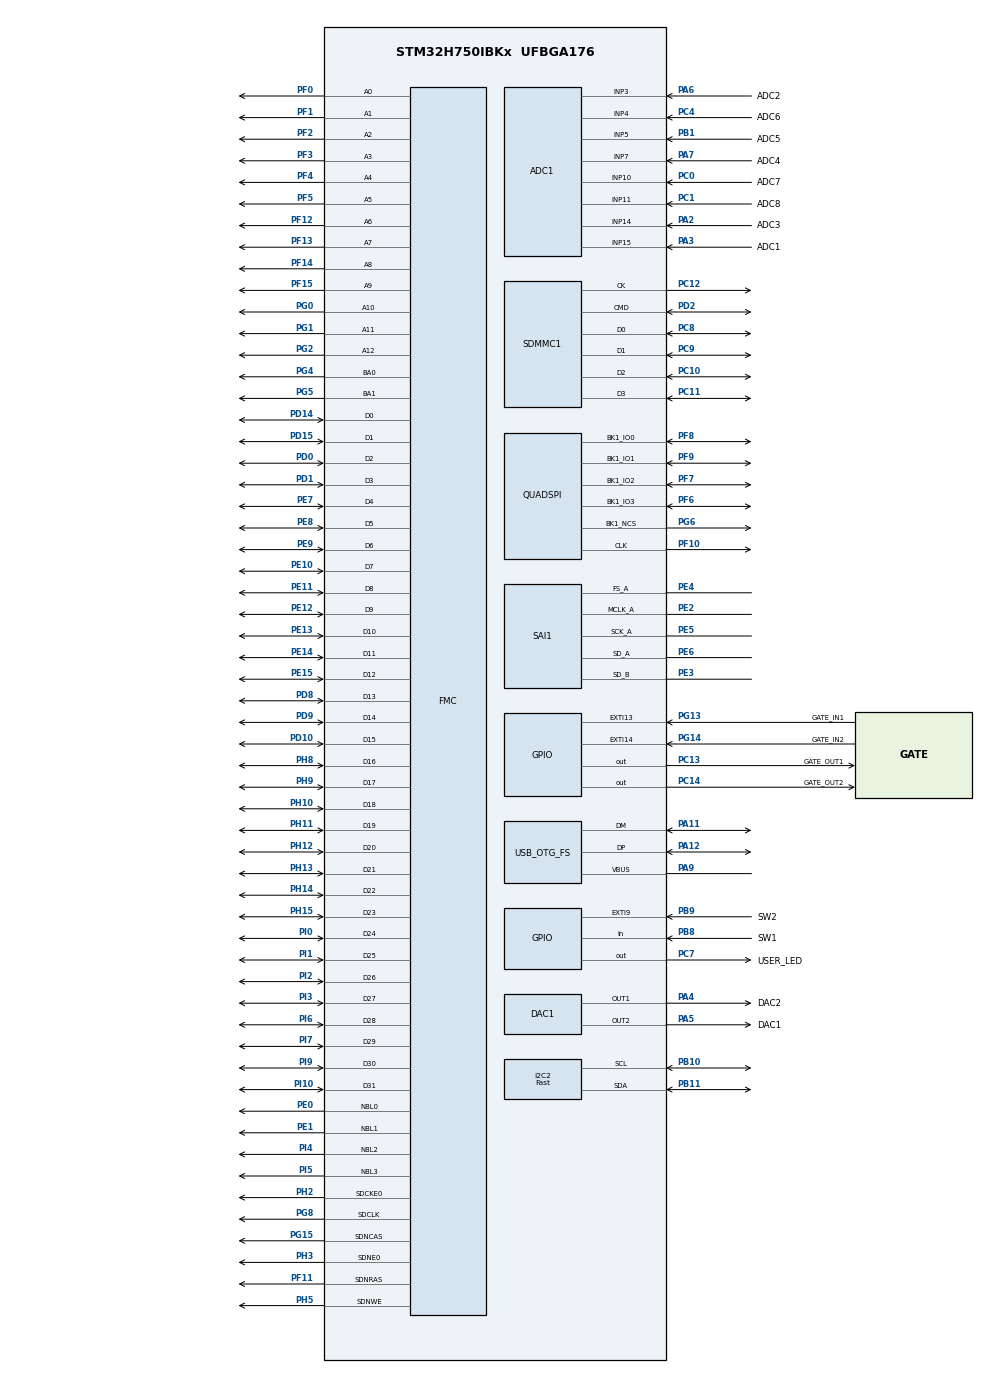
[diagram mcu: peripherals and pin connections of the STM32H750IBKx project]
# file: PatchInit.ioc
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ADC1.Channel-10\#ChannelRegularConversion=ADC_CHANNEL_4
ADC1.Channel-11\#ChannelRegularConversion=ADC_CHANNEL_7
ADC1.Channel-4\#ChannelRegularConversion=ADC_CHANNEL_11
ADC1.Channel-5\#ChannelRegularConversion=ADC_CHANNEL_15
ADC1.Channel-6\#ChannelRegularConversion=ADC_CHANNEL_10
ADC1.Channel-7\#ChannelRegularConversion=ADC_CHANNEL_3
ADC1.Channel-8\#ChannelRegularConversion=ADC_CHANNEL_5
ADC1.Channel-9\#ChannelRegularConversion=ADC_CHANNEL_14
ADC1.ClockPrescaler=ADC_CLOCK_ASYNC_DIV32
ADC1.ContinuousConvMode=ENABLE
ADC1.ConversionDataManagement=ADC_CONVERSIONDATA_DMA_CIRCULAR
ADC1.EOCSelection=ADC_EOC_SEQ_CONV
ADC1.NbrOfConversion=8
ADC1.NbrOfConversionFlag=1
ADC1.OffsetNumber-10\#ChannelRegularConversion=ADC_OFFSET_NONE
ADC1.OffsetNumber-11\#ChannelRegularConversion=ADC_OFFSET_NONE
ADC1.OffsetNumber-4\#ChannelRegularConversion=ADC_OFFSET_NONE
ADC1.OffsetNumber-5\#ChannelRegularConversion=ADC_OFFSET_NONE
ADC1.OffsetNumber-6\#ChannelRegularConversion=ADC_OFFSET_NONE
ADC1.OffsetNumber-7\#ChannelRegularConversion=ADC_OFFSET_NONE
ADC1.OffsetNumber-8\#ChannelRegularConversion=ADC_OFFSET_NONE
ADC1.OffsetNumber-9\#ChannelRegularConversion=ADC_OFFSET_NONE
ADC1.OffsetSignedSaturation-10\#ChannelRegularConversion=DISABLE
ADC1.OffsetSignedSaturation-11\#ChannelRegularConversion=DISABLE
ADC1.OffsetSignedSaturation-4\#ChannelRegularConversion=DISABLE
ADC1.OffsetSignedSaturation-5\#ChannelRegularConversion=DISABLE
ADC1.OffsetSignedSaturation-6\#ChannelRegularConversion=DISABLE
ADC1.OffsetSignedSaturation-7\#ChannelRegularConversion=DISABLE
ADC1.OffsetSignedSaturation-8\#ChannelRegularConversion=DISABLE
ADC1.OffsetSignedSaturation-9\#ChannelRegularConversion=DISABLE
ADC1.Overrun=ADC_OVR_DATA_OVERWRITTEN
ADC1.OversamplingMode=ENABLE
ADC1.Rank-10\#ChannelRegularConversion=7
ADC1.Rank-11\#ChannelRegularConversion=8
ADC1.Rank-4\#ChannelRegularConversion=1
ADC1.Rank-5\#ChannelRegularConversion=2
ADC1.Rank-6\#ChannelRegularConversion=3
ADC1.Rank-7\#ChannelRegularConversion=4
ADC1.Rank-8\#ChannelRegularConversion=5
ADC1.Rank-9\#ChannelRegularConversion=6
ADC1.RightBitShift=ADC_RIGHTBITSHIFT_4
ADC1.SamplingTime-10\#ChannelRegularConversion=ADC_SAMPLETIME_64CYCLES_5
ADC1.SamplingTime-11\#ChannelRegularConversion=ADC_SAMPLETIME_64CYCLES_5
ADC1.SamplingTime-4\#ChannelRegularConversion=ADC_SAMPLETIME_64CYCLES_5
ADC1.SamplingTime-5\#ChannelRegularConversion=ADC_SAMPLETIME_64CYCLES_5
ADC1.SamplingTime-6\#ChannelRegularConversion=ADC_SAMPLETIME_64CYCLES_5
ADC1.SamplingTime-7\#ChannelRegularConversion=ADC_SAMPLETIME_64CYCLES_5
ADC1.SamplingTime-8\#ChannelRegularConversion=ADC_SAMPLETIME_64CYCLES_5
ADC1.SamplingTime-9\#ChannelRegularConversion=ADC_SAMPLETIME_64CYCLES_5
ADC1.master=1
CORTEX_M7.AccessPermission-Cortex_Memory_Protection_Unit_Region0_Settings=MPU_REGION_FULL_ACCESS
CORTEX_M7.BaseAddress-Cortex_Memory_Protection_Unit_Region0_Settings=0xC0000000
CORTEX_M7.CPU_DCache=Enabled
CORTEX_M7.CPU_ICache=Enabled
CORTEX_M7.Enable-Cortex_Memory_Protection_Unit_Region0_Settings=MPU_REGION_ENABLE
CORTEX_M7.IsBufferable-Cortex_Memory_Protection_Unit_Region0_Settings=MPU_ACCESS_BUFFERABLE
CORTEX_M7.IsCacheable-Cortex_Memory_Protection_Unit_Region0_Settings=MPU_ACCESS_CACHEABLE
CORTEX_M7.MPU_Control=__NULL
CORTEX_M7.Size-Cortex_Memory_Protection_Unit_Region0_Settings=MPU_REGION_SIZE_64MB
DAC1.DAC_Channel-DAC_OUT1=DAC_CHANNEL_1
DAC1.DAC_Channel-DAC_OUT2=DAC_CHANNEL_2
DAC1.DAC_Trigger-DAC_OUT1=DAC_TRIGGER_NONE
DAC1.DAC_Trigger-DAC_OUT2=DAC_TRIGGER_NONE
Dma.ADC1.2.Direction=DMA_PERIPH_TO_MEMORY
Dma.ADC1.2.EventEnable=DISABLE
Dma.ADC1.2.FIFOMode=DMA_FIFOMODE_DISABLE
Dma.ADC1.2.Instance=DMA1_Stream0
Dma.ADC1.2.MemDataAlignment=DMA_MDATAALIGN_HALFWORD
Dma.ADC1.2.MemInc=DMA_MINC_ENABLE
Dma.ADC1.2.Mode=DMA_CIRCULAR
Dma.ADC1.2.PeriphDataAlignment=DMA_PDATAALIGN_HALFWORD
Dma.ADC1.2.PeriphInc=DMA_PINC_DISABLE
Dma.ADC1.2.Polarity=HAL_DMAMUX_REQ_GEN_RISING
Dma.ADC1.2.Priority=DMA_PRIORITY_LOW
Dma.ADC1.2.RequestNumber=1
Dma.ADC1.2.SignalID=NONE
Dma.ADC1.2.SyncEnable=DISABLE
Dma.ADC1.2.SyncPolarity=HAL_DMAMUX_SYNC_NO_EVENT
Dma.ADC1.2.SyncRequestNumber=1
Dma.ADC1.2.SyncSignalID=NONE
Dma.Request0=SAI1_A
Dma.Request1=SAI1_B
Dma.Request2=ADC1
Dma.SAI1_A.0.Direction=DMA_PERIPH_TO_MEMORY
Dma.SAI1_A.0.EventEnable=DISABLE
Dma.SAI1_A.0.FIFOMode=DMA_FIFOMODE_DISABLE
Dma.SAI1_A.0.Instance=DMA1_Stream6
Dma.SAI1_A.0.MemDataAlignment=DMA_MDATAALIGN_WORD
Dma.SAI1_A.0.MemInc=DMA_MINC_ENABLE
Dma.SAI1_A.0.Mode=DMA_CIRCULAR
Dma.SAI1_A.0.PeriphDataAlignment=DMA_PDATAALIGN_WORD
Dma.SAI1_A.0.PeriphInc=DMA_PINC_DISABLE
Dma.SAI1_A.0.Polarity=HAL_DMAMUX_REQ_GEN_RISING
Dma.SAI1_A.0.Priority=DMA_PRIORITY_VERY_HIGH
Dma.SAI1_A.0.RequestNumber=1
Dma.SAI1_A.0.SignalID=NONE
Dma.SAI1_A.0.SyncEnable=DISABLE
Dma.SAI1_A.0.SyncPolarity=HAL_DMAMUX_SYNC_NO_EVENT
Dma.SAI1_A.0.SyncRequestNumber=1
Dma.SAI1_A.0.SyncSignalID=NONE
Dma.SAI1_B.1.Direction=DMA_MEMORY_TO_PERIPH
Dma.SAI1_B.1.EventEnable=DISABLE
Dma.SAI1_B.1.FIFOMode=DMA_FIFOMODE_DISABLE
Dma.SAI1_B.1.Instance=DMA1_Stream7
Dma.SAI1_B.1.MemDataAlignment=DMA_MDATAALIGN_WORD
Dma.SAI1_B.1.MemInc=DMA_MINC_ENABLE
Dma.SAI1_B.1.Mode=DMA_CIRCULAR
Dma.SAI1_B.1.PeriphDataAlignment=DMA_PDATAALIGN_WORD
Dma.SAI1_B.1.PeriphInc=DMA_PINC_DISABLE
Dma.SAI1_B.1.Polarity=HAL_DMAMUX_REQ_GEN_RISING
Dma.SAI1_B.1.Priority=DMA_PRIORITY_VERY_HIGH
Dma.SAI1_B.1.RequestNumber=1
Dma.SAI1_B.1.SignalID=NONE
Dma.SAI1_B.1.SyncEnable=DISABLE
Dma.SAI1_B.1.SyncPolarity=HAL_DMAMUX_SYNC_NO_EVENT
Dma.SAI1_B.1.SyncRequestNumber=1
Dma.SAI1_B.1.SyncSignalID=NONE
FMC.CASLatency1=FMC_SDRAM_CAS_LATENCY_3
FMC.ColumnBitsNumber1=FMC_SDRAM_COLUMN_BITS_NUM_9
FMC.ExitSelfRefreshDelay1=7
FMC.LoadToActiveDelay1=2
FMC.RPDelay1=0
FMC.ReadBurst1=FMC_SDRAM_RBURST_ENABLE
FMC.RowCycleDelay1=8
FMC.SDClockPeriod1=FMC_SDRAM_CLOCK_PERIOD_2
FMC.SelfRefreshTime1=4
FMC.WriteRecoveryTime1=3
FREERTOS.INCLUDE_vTaskDelayUntil=1
FREERTOS.Tasks01=defaultTask,0,1024,StartDefaultTask,Default,NULL,Dynamic,NULL,NULL
FREERTOS.configCHECK_FOR_STACK_OVERFLOW=2
FREERTOS.configUSE_MALLOC_FAILED_HOOK=1
FREERTOS.configUSE_MUTEXES=0
FREERTOS.configUSE_PREEMPTION=0
I2C2.I2C_Speed_Mode=I2C_Fast
I2C2.Timing=0x00B03FDB
IWDG1.Prescaler=IWDG_PRESCALER_128
IWDG1.Reload=8*32000/128
IWDG1.Window=8*32000/128
Mcu.Family=STM32H7
Mcu.Name=STM32H750IBKx
Mcu.Package=UFBGA176
NVIC.DMA1_Stream0_IRQn=true\:5\:0\:false\:false\:true\:true\:false\:true
NVIC.DMA1_Stream6_IRQn=true\:5\:0\:true\:false\:true\:false\:false\:true
NVIC.DMA1_Stream7_IRQn=true\:5\:0\:true\:false\:true\:false\:false\:true
NVIC.EXTI15_10_IRQn=true\:5\:0\:false\:false\:true\:true\:true\:true
NVIC.EXTI9_5_IRQn=true\:5\:0\:false\:false\:true\:true\:true\:true
NVIC.OTG_FS_IRQn=true\:10\:0\:true\:false\:true\:false\:false\:true
NVIC.PriorityGroup=NVIC_PRIORITYGROUP_4
NVIC.QUADSPI_IRQn=true\:5\:0\:false\:false\:true\:false\:true\:true
NVIC.SAI1_IRQn=true\:5\:0\:true\:false\:true\:false\:true\:true
NVIC.SDMMC1_IRQn=true\:5\:0\:false\:false\:true\:true\:true\:true
NVIC.TIM6_DAC_IRQn=true\:5\:0\:false\:false\:true\:false\:false\:true
PA11.GPIO_Speed=GPIO_SPEED_FREQ_MEDIUM
PA11.Mode=Device_Only
PA11.Signal=USB_OTG_FS_DM
PA12.GPIO_Speed=GPIO_SPEED_FREQ_MEDIUM
PA12.Mode=Device_Only
PA12.Signal=USB_OTG_FS_DP
PA13\ (JTMS/SWDIO).Mode=JTAG_4_pins
PA13\ (JTMS/SWDIO).Signal=DEBUG_JTMS-SWDIO
PA14\ (JTCK/SWCLK).Mode=JTAG_4_pins
PA14\ (JTCK/SWCLK).Signal=DEBUG_JTCK-SWCLK
PA15\ (JTDI).Mode=JTAG_4_pins
PA15\ (JTDI).Signal=DEBUG_JTDI
PA2.GPIO_Label=ADC3
PA2.Signal=ADCx_INP14
PA3.GPIO_Label=ADC1
PA3.Signal=ADCx_INP15
PA4.GPIO_Label=DAC2
PA4.Signal=COMP_DAC11_group
PA5.GPIO_Label=DAC1
PA5.Signal=COMP_DAC12_group
PA6.GPIO_Label=ADC2
PA6.Signal=ADCx_INP3
PA7.GPIO_Label=ADC4
PA7.Signal=ADCx_INP7
PA9.Mode=Activate_VBUS
PA9.Signal=USB_OTG_FS_VBUS
PB1.GPIO_Label=ADC5
PB1.Signal=ADCx_INP5
PB10.Mode=I2C
PB10.Signal=I2C2_SCL
PB11.Mode=I2C
PB11.Signal=I2C2_SDA
PB3\ (JTDO/TRACESWO).Mode=JTAG_4_pins
PB3\ (JTDO/TRACESWO).Signal=DEBUG_JTDO-SWO
PB8.GPIO_Label=SW1
PB8.GPIO_PuPd=GPIO_PULLUP
PB8.Signal=GPIO_Input
PB9.GPIO_Label=SW2
PB9.GPIO_ModeDefaultEXTI=GPIO_MODE_IT_RISING_FALLING
PB9.GPIO_PuPd=GPIO_PULLUP
PB9.Signal=GPXTI9
PC0.GPIO_Label=ADC7
PC0.Signal=ADCx_INP10
PC1.GPIO_Label=ADC8
PC1.Signal=ADCx_INP11
PC10.Mode=SD_4_bits_Wide_bus
PC10.Signal=SDMMC1_D2
PC11.Mode=SD_4_bits_Wide_bus
PC11.Signal=SDMMC1_D3
PC12.Mode=SD_4_bits_Wide_bus
PC12.Signal=SDMMC1_CK
PC13.GPIO_Label=GATE_OUT1
PC13.Signal=GPIO_Output
PC14-OSC32_IN\ (OSC32_IN).GPIO_Label=GATE_OUT2
PC14-OSC32_IN\ (OSC32_IN).Signal=GPIO_Output
PC4.GPIO_Label=ADC6
PC4.Signal=ADCx_INP4
PC7.GPIO_Label=USER_LED
PC7.Signal=GPIO_Output
PC8.Mode=SD_4_bits_Wide_bus
PC8.Signal=SDMMC1_D0
PC9.Mode=SD_4_bits_Wide_bus
PC9.Signal=SDMMC1_D1
PD0.Signal=FMC_D2_DA2
PD1.Signal=FMC_D3_DA3
PD10.Signal=FMC_D15_DA15
PD14.Signal=FMC_D0_DA0
PD15.Signal=FMC_D1_DA1
PD2.Mode=SD_4_bits_Wide_bus
PD2.Signal=SDMMC1_CMD
PD8.Signal=FMC_D13_DA13
PD9.Signal=FMC_D14_DA14
PE0.Signal=FMC_NBL0
PE1.Signal=FMC_NBL1
PE10.Signal=FMC_D7_DA7
PE11.Signal=FMC_D8_DA8
PE12.Signal=FMC_D9_DA9
PE13.Signal=FMC_D10_DA10
PE14.Signal=FMC_D11_DA11
PE15.Signal=FMC_D12_DA12
PE2.GPIO_Speed=GPIO_SPEED_FREQ_MEDIUM
PE2.Mode=SAI_A_MasterWithClock
PE2.Signal=SAI1_MCLK_A
PE3.GPIO_Speed=GPIO_SPEED_FREQ_MEDIUM
PE3.Mode=SAI_B_SyncSlave
PE3.Signal=SAI1_SD_B
PE4.GPIO_Speed=GPIO_SPEED_FREQ_MEDIUM
PE4.Mode=SAI_A_MasterWithClock
PE4.Signal=SAI1_FS_A
PE5.GPIO_Speed=GPIO_SPEED_FREQ_MEDIUM
PE5.Mode=SAI_A_MasterWithClock
PE5.Signal=SAI1_SCK_A
PE6.GPIO_Speed=GPIO_SPEED_FREQ_MEDIUM
PE6.Mode=SAI_A_MasterWithClock
PE6.Signal=SAI1_SD_A
PE7.Signal=FMC_D4_DA4
PE8.Signal=FMC_D5_DA5
PE9.Signal=FMC_D6_DA6
PF0.Signal=FMC_A0
PF1.Signal=FMC_A1
PF10.GPIO_Speed=GPIO_SPEED_FREQ_VERY_HIGH
PF10.Mode=Single Bank 1
PF10.Signal=QUADSPI_CLK
PF11.Signal=FMC_SDNRAS
PF12.Signal=FMC_A6
PF13.Signal=FMC_A7
PF14.Signal=FMC_A8
PF15.Signal=FMC_A9
PF2.Signal=FMC_A2
PF3.Signal=FMC_A3
PF4.Signal=FMC_A4
PF5.Signal=FMC_A5
PF6.GPIO_Speed=GPIO_SPEED_FREQ_VERY_HIGH
PF6.Mode=Single Bank 1
PF6.Signal=QUADSPI_BK1_IO3
PF7.GPIO_Speed=GPIO_SPEED_FREQ_VERY_HIGH
PF7.Mode=Single Bank 1
PF7.Signal=QUADSPI_BK1_IO2
PF8.GPIO_Speed=GPIO_SPEED_FREQ_VERY_HIGH
PF8.Mode=Single Bank 1
PF8.Signal=QUADSPI_BK1_IO0
PF9.GPIO_Speed=GPIO_SPEED_FREQ_VERY_HIGH
PF9.Mode=Single Bank 1
PF9.Signal=QUADSPI_BK1_IO1
PG0.Signal=FMC_A10
PG1.Signal=FMC_A11
PG13.GPIO_Label=GATE_IN1
PG13.GPIO_ModeDefaultEXTI=GPIO_MODE_IT_RISING_FALLING
PG13.Signal=GPXTI13
PG14.GPIO_Label=GATE_IN2
PG14.GPIO_ModeDefaultEXTI=GPIO_MODE_IT_RISING_FALLING
PG14.Signal=GPXTI14
PG15.Signal=FMC_SDNCAS
PG2.Signal=FMC_A12
PG4.Signal=FMC_A14_BA0
PG5.Signal=FMC_A15_BA1
PG6.GPIO_Speed=GPIO_SPEED_FREQ_VERY_HIGH
PG6.Mode=Single Bank 1
PG6.Signal=QUADSPI_BK1_NCS
PG8.Signal=FMC_SDCLK
PH0-OSC_IN\ (PH0).Mode=HSE-External-Oscillator
PH0-OSC_IN\ (PH0).Signal=RCC_OSC_IN
PH1-OSC_OUT\ (PH1).Mode=HSE-External-Oscillator
PH1-OSC_OUT\ (PH1).Signal=RCC_OSC_OUT
PH10.Signal=FMC_D18
PH11.Signal=FMC_D19
PH12.Signal=FMC_D20
PH13.Signal=FMC_D21
PH14.Signal=FMC_D22
PH15.Signal=FMC_D23
PH2.Mode=SdramChipSelect1_1
PH2.Signal=FMC_SDCKE0
PH3.Mode=SdramChipSelect1_1
PH3.Signal=FMC_SDNE0
PH5.Signal=FMC_SDNWE
PH8.Signal=FMC_D16
PH9.Signal=FMC_D17
PI0.Signal=FMC_D24
PI1.Signal=FMC_D25
PI10.Signal=FMC_D31
PI2.Signal=FMC_D26
PI3.Signal=FMC_D27
PI4.Signal=FMC_NBL2
PI5.Signal=FMC_NBL3
PI6.Signal=FMC_D28
PI7.Signal=FMC_D29
PI9.Signal=FMC_D30
ProjectManager.HeapSize=0x2000
ProjectManager.StackSize=0x4000
ProjectManager.TargetToolchain=Makefile
QUADSPI.ChipSelectHighTime=QSPI_CS_HIGH_TIME_1_CYCLE
QUADSPI.ClockPrescaler=1
RCC.ADCCLockSelection=RCC_ADCCLKSOURCE_CLKP
RCC.ADCFreq_Value=16000000
RCC.APB1Freq_Value=120000000
RCC.APB2Freq_Value=120000000
RCC.APB3Freq_Value=120000000
RCC.APB4Freq_Value=120000000
RCC.CKPERSourceSelection=RCC_CLKPSOURCE_HSE
RCC.CortexFreq_Value=480000000
RCC.D1PPRE=RCC_APB3_DIV2
RCC.D2PPRE1=RCC_APB1_DIV2
RCC.D2PPRE2=RCC_APB2_DIV2
RCC.D3PPRE=RCC_APB4_DIV2
RCC.DATA_CACHE_ENABLE=1
RCC.DIVM1=4
RCC.DIVM2=4
RCC.DIVM3=10
RCC.DIVN1=240
RCC.DIVN2=84
RCC.DIVN3=384
RCC.DIVP2=8
RCC.DIVP3=25
RCC.DIVQ1=5
RCC.DIVQ2=10
RCC.DIVQ3=4
RCC.DIVR3=32
RCC.FMCCLockSelection=RCC_FMCCLKSOURCE_PLL2
RCC.HCLKFreq_Value=240000000
RCC.HPRE=RCC_HCLK_DIV2
RCC.HSE_VALUE=16000000
RCC.INSTRUCTION_CACHE_ENABLE=1
RCC.PLL3FRACN=0
RCC.PLLSourceVirtual=RCC_PLLSOURCE_HSE
RCC.PREFETCH_ENABLE=1
RCC.PWREXT_OverDrive=PWREXT_OverDrive_DESACTIVATED
RCC.SAI1CLockSelection=RCC_SAI1CLKSOURCE_PLL3
RCC.SAI23CLockSelection=RCC_SAI23CLKSOURCE_PLL3
RCC.SPI123CLockSelection=RCC_SPI123CLKSOURCE_PLL2
RCC.SYSCLKFreq_VALUE=480000000
RCC.SYSCLKSource=RCC_SYSCLKSOURCE_PLLCLK
RCC.USBCLockSelection=RCC_USBCLKSOURCE_HSI48
RCC.USBFreq_Value=48000000
SAI1.AudioFrequency-SAI_A_MasterWithClock=SAI_AUDIO_FREQUENCY_48K
SAI1.AudioMode-SAI_A_MasterWithClock=SAI_MODEMASTER_RX
SAI1.AudioMode-SAI_B_SyncSlave=SAI_MODESLAVE_TX
SAI1.BasicDataSize-SAI_A_MasterWithClock=SAI_PROTOCOL_DATASIZE_24BIT
SAI1.BasicDataSize-SAI_B_SyncSlave=SAI_PROTOCOL_DATASIZE_24BIT
SAI1.BasicProtocol-SAI_A_MasterWithClock=SAI_I2S_MSBJUSTIFIED
SAI1.BasicProtocol-SAI_B_SyncSlave=SAI_I2S_MSBJUSTIFIED
SAI1.ErrorAudioFreq-SAI_A_MasterWithClock=0.0 %
SAI1.InitProtocol-SAI_A_MasterWithClock=Enable
SAI1.InitProtocol-SAI_B_SyncSlave=Enable
SAI1.Instance-SAI_A_MasterWithClock=SAI$Index_Block_A
SAI1.Instance-SAI_B_SyncSlave=SAI$Index_Block_B
SAI1.MClockEnable-SAI_A_MasterWithClock=SAI_MASTERCLOCK_ENABLE
SAI1.RealAudioFreq-SAI_A_MasterWithClock=48.0 KHz
SAI1.Synchro_B=SAI_SYNCHRONOUS
SAI1.VirtualMode-SAI_A_MasterWithClock=VM_MASTER
SAI1.VirtualMode-SAI_B_SyncSlave=VM_SLAVE
SAI1.VirtualProtocol-SAI_A_BASIC=VM_BASIC_PROTOCOL
SAI1.VirtualProtocol-SAI_B_BASIC=VM_BASIC_PROTOCOL
SDMMC1.ClockDiv=4
SH.ADCx_INP10.0=ADC1_INP10,IN10-Single-Ended
SH.ADCx_INP11.0=ADC1_INP11,IN11-Single-Ended
SH.ADCx_INP14.0=ADC1_INP14,IN14-Single-Ended
SH.ADCx_INP15.0=ADC1_INP15,IN15-Single-Ended
SH.ADCx_INP3.0=ADC1_INP3,IN3-Single-Ended
SH.ADCx_INP4.0=ADC1_INP4,IN4-Single-Ended
SH.ADCx_INP5.0=ADC1_INP5,IN5-Single-Ended
SH.ADCx_INP7.0=ADC1_INP7,IN7-Single-Ended
SH.COMP_DAC11_group.0=DAC1_OUT1,DAC_OUT1
SH.COMP_DAC12_group.0=DAC1_OUT2,DAC_OUT2
SH.FMC_A0.0=FMC_A0,13b-sda1
SH.FMC_A1.0=FMC_A1,13b-sda1
SH.FMC_A10.0=FMC_A10,13b-sda1
SH.FMC_A11.0=FMC_A11,13b-sda1
SH.FMC_A12.0=FMC_A12,13b-sda1
SH.FMC_A14_BA0.0=FMC_BA0,FourSdramBanks1
SH.FMC_A15_BA1.0=FMC_BA1,FourSdramBanks1
SH.FMC_A2.0=FMC_A2,13b-sda1
SH.FMC_A3.0=FMC_A3,13b-sda1
SH.FMC_A4.0=FMC_A4,13b-sda1
SH.FMC_A5.0=FMC_A5,13b-sda1
SH.FMC_A6.0=FMC_A6,13b-sda1
SH.FMC_A7.0=FMC_A7,13b-sda1
SH.FMC_A8.0=FMC_A8,13b-sda1
SH.FMC_A9.0=FMC_A9,13b-sda1
SH.FMC_D0_DA0.0=FMC_D0,sd-32b-d1
SH.FMC_D10_DA10.0=FMC_D10,sd-32b-d1
SH.FMC_D11_DA11.0=FMC_D11,sd-32b-d1
SH.FMC_D12_DA12.0=FMC_D12,sd-32b-d1
SH.FMC_D13_DA13.0=FMC_D13,sd-32b-d1
SH.FMC_D14_DA14.0=FMC_D14,sd-32b-d1
SH.FMC_D15_DA15.0=FMC_D15,sd-32b-d1
SH.FMC_D16.0=FMC_D16,sd-32b-d1
SH.FMC_D17.0=FMC_D17,sd-32b-d1
SH.FMC_D18.0=FMC_D18,sd-32b-d1
SH.FMC_D19.0=FMC_D19,sd-32b-d1
SH.FMC_D1_DA1.0=FMC_D1,sd-32b-d1
SH.FMC_D20.0=FMC_D20,sd-32b-d1
SH.FMC_D21.0=FMC_D21,sd-32b-d1
SH.FMC_D22.0=FMC_D22,sd-32b-d1
SH.FMC_D23.0=FMC_D23,sd-32b-d1
SH.FMC_D24.0=FMC_D24,sd-32b-d1
SH.FMC_D25.0=FMC_D25,sd-32b-d1
SH.FMC_D26.0=FMC_D26,sd-32b-d1
SH.FMC_D27.0=FMC_D27,sd-32b-d1
SH.FMC_D28.0=FMC_D28,sd-32b-d1
SH.FMC_D29.0=FMC_D29,sd-32b-d1
SH.FMC_D2_DA2.0=FMC_D2,sd-32b-d1
SH.FMC_D30.0=FMC_D30,sd-32b-d1
SH.FMC_D31.0=FMC_D31,sd-32b-d1
SH.FMC_D3_DA3.0=FMC_D3,sd-32b-d1
SH.FMC_D4_DA4.0=FMC_D4,sd-32b-d1
SH.FMC_D5_DA5.0=FMC_D5,sd-32b-d1
SH.FMC_D6_DA6.0=FMC_D6,sd-32b-d1
SH.FMC_D7_DA7.0=FMC_D7,sd-32b-d1
SH.FMC_D8_DA8.0=FMC_D8,sd-32b-d1
SH.FMC_D9_DA9.0=FMC_D9,sd-32b-d1
SH.FMC_NBL0.0=FMC_NBL0,Sd4ByteEnable1
SH.FMC_NBL1.0=FMC_NBL1,Sd4ByteEnable1
SH.FMC_NBL2.0=FMC_NBL2,Sd4ByteEnable1
SH.FMC_NBL3.0=FMC_NBL3,Sd4ByteEnable1
SH.FMC_SDCLK.0=FMC_SDCLK,13b-sda1
SH.FMC_SDNCAS.0=FMC_SDNCAS,13b-sda1
SH.FMC_SDNRAS.0=FMC_SDNRAS,13b-sda1
SH.FMC_SDNWE.0=FMC_SDNWE,13b-sda1
USB_DEVICE.CLASS_NAME_FS=AUDIO
USB_DEVICE.MANUFACTURER_STRING-AUDIO_FS=Electrosmith
USB_DEVICE.PID_AUDIO_FS=0xDADA
USB_DEVICE.PRODUCT_STRING_AUDIO_FS=OWL-INIT
USB_DEVICE.USBD_AUDIO_FREQ-AUDIO_FS=48000
USB_DEVICE.USBD_MAX_NUM_CONFIGURATION-AUDIO_FS=1
USB_DEVICE.USBD_MAX_NUM_INTERFACES-AUDIO_FS=3
USB_DEVICE.VID-AUDIO_FS=0x1155
USB_DEVICE.VirtualMode-AUDIO_FS=Audio
USB_DEVICE.VirtualModeFS=Audio_FS
USB_OTG_FS.VirtualMode=Device_Only
USB_OTG_FS.battery_charging_enable=DISABLE
VP_FREERTOS_VS_CMSIS_V1.Mode=CMSIS_V1
VP_IWDG1_VS_IWDG.Mode=IWDG_Activate
VP_SAI1_VP_$IpInstance_SAIA_SAI_BASIC.Mode=SAI_A_BASIC
VP_SAI1_VP_$IpInstance_SAIB_SAI_BASIC.Mode=SAI_B_BASIC
VP_USB_DEVICE_VS_USB_DEVICE_AUDIO_FS.Mode=AUDIO_FS
board=custom

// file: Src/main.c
/* USER CODE BEGIN Header */
/**
  ******************************************************************************
  * @file           : main.c
  * @brief          : Main program body
  ******************************************************************************
  * @attention
  *
  * <h2><center>&copy; Copyright (c) 2020 STMicroelectronics.
  * All rights reserved.</center></h2>
  *
  * This software component is licensed by ST under Ultimate Liberty license
  * SLA0044, the "License"; You may not use this file except in compliance with
  * the License. You may obtain a copy of the License at:
  *                             www.st.com/SLA0044
  *
  ******************************************************************************
  */
/* USER CODE END Header */
#include "main.h"
#include "cmsis_os.h"
#include "usb_device.h"

/* USER CODE BEGIN Includes */
#include "device.h"
#include "errorhandlers.h"
#include "sdram.h"
#include "qspicontrol.h"
#include "fatfs.h"
#include <stdbool.h>
/* USER CODE END Includes */

ADC_HandleTypeDef hadc1;
DMA_HandleTypeDef hdma_adc1;

DAC_HandleTypeDef hdac1;

I2C_HandleTypeDef hi2c2;

IWDG_HandleTypeDef hiwdg1;

QSPI_HandleTypeDef hqspi;

SAI_HandleTypeDef hsai_BlockA1;
SAI_HandleTypeDef hsai_BlockB1;
DMA_HandleTypeDef hdma_sai1_a;
DMA_HandleTypeDef hdma_sai1_b;

SD_HandleTypeDef hsd1;

SDRAM_HandleTypeDef hsdram1;

osThreadId defaultTaskHandle;

void SystemClock_Config(void);
void PeriphCommonClock_Config(void);
static void MX_GPIO_Init(void);
static void MX_DMA_Init(void);
static void MX_FMC_Init(void);
static void MX_IWDG1_Init(void);
static void MX_ADC1_Init(void);
static void MX_DAC1_Init(void);
static void MX_SAI1_Init(void);
static void MX_QUADSPI_Init(void);
static void MX_SDMMC1_SD_Init(void);
static void MX_I2C2_Init(void);
void StartDefaultTask(void const * argument);

/* USER CODE BEGIN PFP */
void setup(void);
void loop(void);
//void MX_USB_HOST_Process(void);
void SDRAM_Initialization_Sequence(SDRAM_HandleTypeDef *hsdram);
void initialise_monitor_handles(void);

/* USER CODE END PFP */

int main(void)
{
  /* USER CODE BEGIN 1 */

#ifdef DEBUG
#warning "DEBUG uses printf and semihosting!"
  if(CoreDebug->DHCSR & 0x01)
    initialise_monitor_handles(); // remove when not semi-hosting
  printf("showtime\n");
#endif
  MPU_Config();

#ifdef USE_CACHE
  /* USER CODE END 1 */

  /* Enable I-Cache---------------------------------------------------------*/
  SCB_EnableICache();

  /* Enable D-Cache---------------------------------------------------------*/
  SCB_EnableDCache();

  /* MCU Configuration--------------------------------------------------------*/

  /* Reset of all peripherals, Initializes the Flash interface and the Systick. */
  HAL_Init();

  /* USER CODE BEGIN Init */
#else
  HAL_Init();
#endif

  /* USER CODE END Init */

  /* Configure the system clock */
  SystemClock_Config();

/* Configure the peripherals common clocks */
  PeriphCommonClock_Config();

  /* Initialize all configured peripherals */
  MX_GPIO_Init();
  MX_DMA_Init();
  MX_FMC_Init();
  MX_IWDG1_Init();
  MX_ADC1_Init();
  MX_DAC1_Init();
  MX_SAI1_Init();
  MX_QUADSPI_Init();
//  MX_SDMMC1_SD_Init();
  MX_I2C2_Init();
  /* USER CODE BEGIN 2 */

  //HAL_NVIC_SetPriority(EXTI2_IRQn, 3, 0);
  //HAL_NVIC_EnableIRQ(EXTI2_IRQn);
  //HAL_NVIC_EnableIRQ(OTG_FS_IRQn)

  SDRAM_Initialization_Sequence(&hsdram1);
  MX_SDMMC1_SD_Init();

  /* USER CODE END 2 */

  /* Create the thread(s) */
  /* definition and creation of defaultTask */
  osThreadDef(defaultTask, StartDefaultTask, osPriorityNormal, 0, 1024);
  defaultTaskHandle = osThreadCreate(osThread(defaultTask), NULL);

  /* Start scheduler */
  osKernelStart();

  /* We should never get here as control is now taken by the scheduler */
  /* Infinite loop */
  while (1)
  {

  }
}

void SystemClock_Config(void)
{
  RCC_OscInitTypeDef RCC_OscInitStruct = {0};
  RCC_ClkInitTypeDef RCC_ClkInitStruct = {0};

  /** Supply configuration update enable
  */
  HAL_PWREx_ConfigSupply(PWR_LDO_SUPPLY);
  /** Configure the main internal regulator output voltage
  */
  __HAL_PWR_VOLTAGESCALING_CONFIG(PWR_REGULATOR_VOLTAGE_SCALE0);

  while(!__HAL_PWR_GET_FLAG(PWR_FLAG_VOSRDY)) {}
  /** Macro to configure the PLL clock source
  */
  __HAL_RCC_PLL_PLLSOURCE_CONFIG(RCC_PLLSOURCE_HSE);
  /** Initializes the RCC Oscillators according to the specified parameters
  * in the RCC_OscInitTypeDef structure.
  */
  RCC_OscInitStruct.OscillatorType = RCC_OSCILLATORTYPE_HSI48|RCC_OSCILLATORTYPE_LSI
                              |RCC_OSCILLATORTYPE_HSE;
  RCC_OscInitStruct.HSEState = RCC_HSE_ON;
  RCC_OscInitStruct.LSIState = RCC_LSI_ON;
  RCC_OscInitStruct.HSI48State = RCC_HSI48_ON;
  RCC_OscInitStruct.PLL.PLLState = RCC_PLL_ON;
  RCC_OscInitStruct.PLL.PLLSource = RCC_PLLSOURCE_HSE;
  RCC_OscInitStruct.PLL.PLLM = 4;
  RCC_OscInitStruct.PLL.PLLN = 240;
  RCC_OscInitStruct.PLL.PLLP = 2;
  RCC_OscInitStruct.PLL.PLLQ = 5;
  RCC_OscInitStruct.PLL.PLLR = 2;
  RCC_OscInitStruct.PLL.PLLRGE = RCC_PLL1VCIRANGE_2;
  RCC_OscInitStruct.PLL.PLLVCOSEL = RCC_PLL1VCOWIDE;
  RCC_OscInitStruct.PLL.PLLFRACN = 0;
  if (HAL_RCC_OscConfig(&RCC_OscInitStruct) != HAL_OK)
  {
    Error_Handler();
  }
  /** Initializes the CPU, AHB and APB buses clocks
  */
  RCC_ClkInitStruct.ClockType = RCC_CLOCKTYPE_HCLK|RCC_CLOCKTYPE_SYSCLK
                              |RCC_CLOCKTYPE_PCLK1|RCC_CLOCKTYPE_PCLK2
                              |RCC_CLOCKTYPE_D3PCLK1|RCC_CLOCKTYPE_D1PCLK1;
  RCC_ClkInitStruct.SYSCLKSource = RCC_SYSCLKSOURCE_PLLCLK;
  RCC_ClkInitStruct.SYSCLKDivider = RCC_SYSCLK_DIV1;
  RCC_ClkInitStruct.AHBCLKDivider = RCC_HCLK_DIV2;
  RCC_ClkInitStruct.APB3CLKDivider = RCC_APB3_DIV2;
  RCC_ClkInitStruct.APB1CLKDivider = RCC_APB1_DIV2;
  RCC_ClkInitStruct.APB2CLKDivider = RCC_APB2_DIV2;
  RCC_ClkInitStruct.APB4CLKDivider = RCC_APB4_DIV2;

  if (HAL_RCC_ClockConfig(&RCC_ClkInitStruct, FLASH_LATENCY_4) != HAL_OK)
  {
    Error_Handler();
  }
}

void PeriphCommonClock_Config(void)
{
  RCC_PeriphCLKInitTypeDef PeriphClkInitStruct = {0};

  /** Initializes the peripherals clock
  */
  PeriphClkInitStruct.PeriphClockSelection = RCC_PERIPHCLK_SAI1|RCC_PERIPHCLK_CKPER;
  PeriphClkInitStruct.PLL3.PLL3M = 10;
  PeriphClkInitStruct.PLL3.PLL3N = 384;
  PeriphClkInitStruct.PLL3.PLL3P = 25;
  PeriphClkInitStruct.PLL3.PLL3Q = 4;
  PeriphClkInitStruct.PLL3.PLL3R = 32;
  PeriphClkInitStruct.PLL3.PLL3RGE = RCC_PLL3VCIRANGE_0;
  PeriphClkInitStruct.PLL3.PLL3VCOSEL = RCC_PLL3VCOWIDE;
  PeriphClkInitStruct.PLL3.PLL3FRACN = 0;
  PeriphClkInitStruct.CkperClockSelection = RCC_CLKPSOURCE_HSE;
  PeriphClkInitStruct.Sai1ClockSelection = RCC_SAI1CLKSOURCE_PLL3;
  if (HAL_RCCEx_PeriphCLKConfig(&PeriphClkInitStruct) != HAL_OK)
  {
    Error_Handler();
  }
}

static void MX_ADC1_Init(void)
{

  ADC_MultiModeTypeDef multimode = {0};
  ADC_ChannelConfTypeDef sConfig = {0};

  /** Common config
  */
  hadc1.Instance = ADC1;
  hadc1.Init.ClockPrescaler = ADC_CLOCK_ASYNC_DIV32;
  hadc1.Init.Resolution = ADC_RESOLUTION_16B;
  hadc1.Init.ScanConvMode = ADC_SCAN_ENABLE;
  hadc1.Init.EOCSelection = ADC_EOC_SEQ_CONV;
  hadc1.Init.LowPowerAutoWait = DISABLE;
  hadc1.Init.ContinuousConvMode = ENABLE;
  hadc1.Init.NbrOfConversion = 8;
  hadc1.Init.DiscontinuousConvMode = DISABLE;
  hadc1.Init.ExternalTrigConv = ADC_SOFTWARE_START;
  hadc1.Init.ExternalTrigConvEdge = ADC_EXTERNALTRIGCONVEDGE_NONE;
  hadc1.Init.ConversionDataManagement = ADC_CONVERSIONDATA_DMA_CIRCULAR;
  hadc1.Init.Overrun = ADC_OVR_DATA_OVERWRITTEN;
  hadc1.Init.LeftBitShift = ADC_LEFTBITSHIFT_NONE;
  hadc1.Init.OversamplingMode = ENABLE;
  hadc1.Init.Oversampling.Ratio = 1;
  hadc1.Init.Oversampling.RightBitShift = ADC_RIGHTBITSHIFT_4;
  hadc1.Init.Oversampling.TriggeredMode = ADC_TRIGGEREDMODE_SINGLE_TRIGGER;
  hadc1.Init.Oversampling.OversamplingStopReset = ADC_REGOVERSAMPLING_CONTINUED_MODE;
  if (HAL_ADC_Init(&hadc1) != HAL_OK)
  {
    Error_Handler();
  }
  /** Configure the ADC multi-mode
  */
  multimode.Mode = ADC_MODE_INDEPENDENT;
  if (HAL_ADCEx_MultiModeConfigChannel(&hadc1, &multimode) != HAL_OK)
  {
    Error_Handler();
  }
  /** Configure Regular Channel
  */
  sConfig.Channel = ADC_CHANNEL_11;
  sConfig.Rank = ADC_REGULAR_RANK_1;
  sConfig.SamplingTime = ADC_SAMPLETIME_64CYCLES_5;
  sConfig.SingleDiff = ADC_SINGLE_ENDED;
  sConfig.OffsetNumber = ADC_OFFSET_NONE;
  sConfig.Offset = 0;
  sConfig.OffsetSignedSaturation = DISABLE;
  if (HAL_ADC_ConfigChannel(&hadc1, &sConfig) != HAL_OK)
  {
    Error_Handler();
  }
  /** Configure Regular Channel
  */
  sConfig.Channel = ADC_CHANNEL_15;
  sConfig.Rank = ADC_REGULAR_RANK_2;
  if (HAL_ADC_ConfigChannel(&hadc1, &sConfig) != HAL_OK)
  {
    Error_Handler();
  }
  /** Configure Regular Channel
  */
  sConfig.Channel = ADC_CHANNEL_10;
  sConfig.Rank = ADC_REGULAR_RANK_3;
  if (HAL_ADC_ConfigChannel(&hadc1, &sConfig) != HAL_OK)
  {
    Error_Handler();
  }
  /** Configure Regular Channel
  */
  sConfig.Channel = ADC_CHANNEL_3;
  sConfig.Rank = ADC_REGULAR_RANK_4;
  if (HAL_ADC_ConfigChannel(&hadc1, &sConfig) != HAL_OK)
  {
    Error_Handler();
  }
  /** Configure Regular Channel
  */
  sConfig.Channel = ADC_CHANNEL_5;
  sConfig.Rank = ADC_REGULAR_RANK_5;
  if (HAL_ADC_ConfigChannel(&hadc1, &sConfig) != HAL_OK)
  {
    Error_Handler();
  }
  /** Configure Regular Channel
  */
  sConfig.Channel = ADC_CHANNEL_14;
  sConfig.Rank = ADC_REGULAR_RANK_6;
  if (HAL_ADC_ConfigChannel(&hadc1, &sConfig) != HAL_OK)
  {
    Error_Handler();
  }
  /** Configure Regular Channel
  */
  sConfig.Channel = ADC_CHANNEL_4;
  sConfig.Rank = ADC_REGULAR_RANK_7;
  if (HAL_ADC_ConfigChannel(&hadc1, &sConfig) != HAL_OK)
  {
    Error_Handler();
  }
  /** Configure Regular Channel
  */
  sConfig.Channel = ADC_CHANNEL_7;
  sConfig.Rank = ADC_REGULAR_RANK_8;
  if (HAL_ADC_ConfigChannel(&hadc1, &sConfig) != HAL_OK)
  {
    Error_Handler();
  }

}

static void MX_DAC1_Init(void)
{

  DAC_ChannelConfTypeDef sConfig = {0};

  /** DAC Initialization
  */
  hdac1.Instance = DAC1;
  if (HAL_DAC_Init(&hdac1) != HAL_OK)
  {
    Error_Handler();
  }
  /** DAC channel OUT1 config
  */
  sConfig.DAC_SampleAndHold = DAC_SAMPLEANDHOLD_DISABLE;
  sConfig.DAC_Trigger = DAC_TRIGGER_NONE;
  sConfig.DAC_OutputBuffer = DAC_OUTPUTBUFFER_ENABLE;
  sConfig.DAC_ConnectOnChipPeripheral = DAC_CHIPCONNECT_DISABLE;
  sConfig.DAC_UserTrimming = DAC_TRIMMING_FACTORY;
  if (HAL_DAC_ConfigChannel(&hdac1, &sConfig, DAC_CHANNEL_1) != HAL_OK)
  {
    Error_Handler();
  }
  /** DAC channel OUT2 config
  */
  if (HAL_DAC_ConfigChannel(&hdac1, &sConfig, DAC_CHANNEL_2) != HAL_OK)
  {
    Error_Handler();
  }

}

static void MX_I2C2_Init(void)
{

  hi2c2.Instance = I2C2;
  hi2c2.Init.Timing = 0x00B03FDB;
  hi2c2.Init.OwnAddress1 = 0;
  hi2c2.Init.AddressingMode = I2C_ADDRESSINGMODE_7BIT;
  hi2c2.Init.DualAddressMode = I2C_DUALADDRESS_DISABLE;
  hi2c2.Init.OwnAddress2 = 0;
  hi2c2.Init.OwnAddress2Masks = I2C_OA2_NOMASK;
  hi2c2.Init.GeneralCallMode = I2C_GENERALCALL_DISABLE;
  hi2c2.Init.NoStretchMode = I2C_NOSTRETCH_DISABLE;
  if (HAL_I2C_Init(&hi2c2) != HAL_OK)
  {
    Error_Handler();
  }
  /** Configure Analogue filter
  */
  if (HAL_I2CEx_ConfigAnalogFilter(&hi2c2, I2C_ANALOGFILTER_ENABLE) != HAL_OK)
  {
    Error_Handler();
  }
  /** Configure Digital filter
  */
  if (HAL_I2CEx_ConfigDigitalFilter(&hi2c2, 0) != HAL_OK)
  {
    Error_Handler();
  }

}

static void MX_IWDG1_Init(void)
{

  /* USER CODE BEGIN IWDG1_Init 1 */
#ifdef USE_IWDG
  /* USER CODE END IWDG1_Init 1 */
  hiwdg1.Instance = IWDG1;
  hiwdg1.Init.Prescaler = IWDG_PRESCALER_128;
  hiwdg1.Init.Window = 8*32000/128;
  hiwdg1.Init.Reload = 8*32000/128;
  if (HAL_IWDG_Init(&hiwdg1) != HAL_OK)
  {
    Error_Handler();
  }
  /* USER CODE BEGIN IWDG1_Init 2 */
#endif
  /* USER CODE END IWDG1_Init 2 */

}

static void MX_QUADSPI_Init(void)
{

  /* USER CODE BEGIN QUADSPI_Init 0 */
// Somehow initializing it here leads to FW hanging, we'll do it later from code copied from Daisy
#if 0
  /* USER CODE END QUADSPI_Init 0 */

  /* QUADSPI parameter configuration*/
  hqspi.Instance = QUADSPI;
  hqspi.Init.ClockPrescaler = 1;
  hqspi.Init.FifoThreshold = 1;
  hqspi.Init.SampleShifting = QSPI_SAMPLE_SHIFTING_NONE;
  hqspi.Init.FlashSize = 1;
  hqspi.Init.ChipSelectHighTime = QSPI_CS_HIGH_TIME_1_CYCLE;
  hqspi.Init.ClockMode = QSPI_CLOCK_MODE_0;
  hqspi.Init.FlashID = QSPI_FLASH_ID_1;
  hqspi.Init.DualFlash = QSPI_DUALFLASH_DISABLE;
  if (HAL_QSPI_Init(&hqspi) != HAL_OK)
  {
    Error_Handler();
  }
  /* USER CODE BEGIN QUADSPI_Init 2 */
#endif
  /* USER CODE END QUADSPI_Init 2 */

}

static void MX_SAI1_Init(void)
{

  hsai_BlockA1.Instance = SAI1_Block_A;
  hsai_BlockA1.Init.AudioMode = SAI_MODEMASTER_RX;
  hsai_BlockA1.Init.Synchro = SAI_ASYNCHRONOUS;
  hsai_BlockA1.Init.OutputDrive = SAI_OUTPUTDRIVE_DISABLE;
  hsai_BlockA1.Init.NoDivider = SAI_MASTERDIVIDER_ENABLE;
  hsai_BlockA1.Init.FIFOThreshold = SAI_FIFOTHRESHOLD_EMPTY;
  hsai_BlockA1.Init.AudioFrequency = SAI_AUDIO_FREQUENCY_48K;
  hsai_BlockA1.Init.SynchroExt = SAI_SYNCEXT_DISABLE;
  hsai_BlockA1.Init.MonoStereoMode = SAI_STEREOMODE;
  hsai_BlockA1.Init.CompandingMode = SAI_NOCOMPANDING;
  if (HAL_SAI_InitProtocol(&hsai_BlockA1, SAI_I2S_MSBJUSTIFIED, SAI_PROTOCOL_DATASIZE_24BIT, 2) != HAL_OK)
  {
    Error_Handler();
  }
  hsai_BlockB1.Instance = SAI1_Block_B;
  hsai_BlockB1.Init.AudioMode = SAI_MODESLAVE_TX;
  hsai_BlockB1.Init.Synchro = SAI_SYNCHRONOUS;
  hsai_BlockB1.Init.OutputDrive = SAI_OUTPUTDRIVE_DISABLE;
  hsai_BlockB1.Init.FIFOThreshold = SAI_FIFOTHRESHOLD_EMPTY;
  hsai_BlockB1.Init.SynchroExt = SAI_SYNCEXT_DISABLE;
  hsai_BlockB1.Init.MonoStereoMode = SAI_STEREOMODE;
  hsai_BlockB1.Init.CompandingMode = SAI_NOCOMPANDING;
  hsai_BlockB1.Init.TriState = SAI_OUTPUT_NOTRELEASED;
  if (HAL_SAI_InitProtocol(&hsai_BlockB1, SAI_I2S_MSBJUSTIFIED, SAI_PROTOCOL_DATASIZE_24BIT, 2) != HAL_OK)
  {
    Error_Handler();
  }

}

static void MX_SDMMC1_SD_Init(void)
{

  /* USER CODE BEGIN SDMMC1_Init 1 */
#if 0
  /* USER CODE END SDMMC1_Init 1 */
  hsd1.Instance = SDMMC1;
  hsd1.Init.ClockEdge = SDMMC_CLOCK_EDGE_RISING;
  hsd1.Init.ClockPowerSave = SDMMC_CLOCK_POWER_SAVE_DISABLE;
  hsd1.Init.BusWide = SDMMC_BUS_WIDE_4B;
  hsd1.Init.HardwareFlowControl = SDMMC_HARDWARE_FLOW_CONTROL_DISABLE;
  hsd1.Init.ClockDiv = 4;
  if (HAL_SD_Init(&hsd1) != HAL_OK)
  {
    Error_Handler();
  }
  /* USER CODE BEGIN SDMMC1_Init 2 */
#endif
  hsd1.Instance = SDMMC1;
  hsd1.Init.ClockEdge = SDMMC_CLOCK_EDGE_RISING;
  hsd1.Init.ClockPowerSave = SDMMC_CLOCK_POWER_SAVE_DISABLE;
  hsd1.Init.BusWide = SDMMC_BUS_WIDE_4B;
  hsd1.Init.HardwareFlowControl = SDMMC_HARDWARE_FLOW_CONTROL_DISABLE;
  hsd1.Init.ClockDiv = 4;
  if (HAL_SD_Init(&hsd1) == HAL_OK)
  {
    MX_FATFS_Init();
    extern bool sd_initialized;
    sd_initialized = true;
  }
  /* USER CODE END SDMMC1_Init 2 */

}

static void MX_DMA_Init(void)
{

  /* DMA controller clock enable */
  __HAL_RCC_DMA1_CLK_ENABLE();

  /* DMA interrupt init */
  /* DMA1_Stream0_IRQn interrupt configuration */
  HAL_NVIC_SetPriority(DMA1_Stream0_IRQn, 5, 0);
  HAL_NVIC_EnableIRQ(DMA1_Stream0_IRQn);
  /* DMA1_Stream6_IRQn interrupt configuration */
  HAL_NVIC_SetPriority(DMA1_Stream6_IRQn, 5, 0);
  HAL_NVIC_EnableIRQ(DMA1_Stream6_IRQn);
  /* DMA1_Stream7_IRQn interrupt configuration */
  HAL_NVIC_SetPriority(DMA1_Stream7_IRQn, 5, 0);
  HAL_NVIC_EnableIRQ(DMA1_Stream7_IRQn);

}

/* FMC initialization function */
static void MX_FMC_Init(void)
{

  FMC_SDRAM_TimingTypeDef SdramTiming = {0};

  /** Perform the SDRAM1 memory initialization sequence
  */
  hsdram1.Instance = FMC_SDRAM_DEVICE;
  /* hsdram1.Init */
  hsdram1.Init.SDBank = FMC_SDRAM_BANK1;
  hsdram1.Init.ColumnBitsNumber = FMC_SDRAM_COLUMN_BITS_NUM_9;
  hsdram1.Init.RowBitsNumber = FMC_SDRAM_ROW_BITS_NUM_13;
  hsdram1.Init.MemoryDataWidth = FMC_SDRAM_MEM_BUS_WIDTH_32;
  hsdram1.Init.InternalBankNumber = FMC_SDRAM_INTERN_BANKS_NUM_4;
  hsdram1.Init.CASLatency = FMC_SDRAM_CAS_LATENCY_3;
  hsdram1.Init.WriteProtection = FMC_SDRAM_WRITE_PROTECTION_DISABLE;
  hsdram1.Init.SDClockPeriod = FMC_SDRAM_CLOCK_PERIOD_2;
  hsdram1.Init.ReadBurst = FMC_SDRAM_RBURST_ENABLE;
  hsdram1.Init.ReadPipeDelay = FMC_SDRAM_RPIPE_DELAY_0;
  /* SdramTiming */
  SdramTiming.LoadToActiveDelay = 2;
  SdramTiming.ExitSelfRefreshDelay = 7;
  SdramTiming.SelfRefreshTime = 4;
  SdramTiming.RowCycleDelay = 8;
  SdramTiming.WriteRecoveryTime = 3;
  SdramTiming.RPDelay = 0;
  SdramTiming.RCDDelay = 16;

  if (HAL_SDRAM_Init(&hsdram1, &SdramTiming) != HAL_OK)
  {
    Error_Handler( );
  }

}

static void MX_GPIO_Init(void)
{
  GPIO_InitTypeDef GPIO_InitStruct = {0};

  /* GPIO Ports Clock Enable */
  __HAL_RCC_GPIOE_CLK_ENABLE();
  __HAL_RCC_GPIOB_CLK_ENABLE();
  __HAL_RCC_GPIOG_CLK_ENABLE();
  __HAL_RCC_GPIOC_CLK_ENABLE();
  __HAL_RCC_GPIOA_CLK_ENABLE();
  __HAL_RCC_GPIOD_CLK_ENABLE();
  __HAL_RCC_GPIOI_CLK_ENABLE();
  __HAL_RCC_GPIOH_CLK_ENABLE();
  __HAL_RCC_GPIOF_CLK_ENABLE();

  /*Configure GPIO pin Output Level */
  HAL_GPIO_WritePin(GPIOC, GATE_OUT1_Pin|GATE_OUT2_Pin|USER_LED_Pin, GPIO_PIN_RESET);

  /*Configure GPIO pin : SW1_Pin */
  GPIO_InitStruct.Pin = SW1_Pin;
  GPIO_InitStruct.Mode = GPIO_MODE_INPUT;
  GPIO_InitStruct.Pull = GPIO_PULLUP;
  HAL_GPIO_Init(SW1_GPIO_Port, &GPIO_InitStruct);

  /*Configure GPIO pins : GATE_IN2_Pin GATE_IN1_Pin */
  GPIO_InitStruct.Pin = GATE_IN2_Pin|GATE_IN1_Pin;
  GPIO_InitStruct.Mode = GPIO_MODE_IT_RISING_FALLING;
  GPIO_InitStruct.Pull = GPIO_NOPULL;
  HAL_GPIO_Init(GPIOG, &GPIO_InitStruct);

  /*Configure GPIO pin : SW2_Pin */
  GPIO_InitStruct.Pin = SW2_Pin;
  GPIO_InitStruct.Mode = GPIO_MODE_IT_RISING_FALLING;
  GPIO_InitStruct.Pull = GPIO_PULLUP;
  HAL_GPIO_Init(SW2_GPIO_Port, &GPIO_InitStruct);

  /*Configure GPIO pins : GATE_OUT1_Pin GATE_OUT2_Pin USER_LED_Pin */
  GPIO_InitStruct.Pin = GATE_OUT1_Pin|GATE_OUT2_Pin|USER_LED_Pin;
  GPIO_InitStruct.Mode = GPIO_MODE_OUTPUT_PP;
  GPIO_InitStruct.Pull = GPIO_NOPULL;
  GPIO_InitStruct.Speed = GPIO_SPEED_FREQ_LOW;
  HAL_GPIO_Init(GPIOC, &GPIO_InitStruct);

  /* EXTI interrupt init*/
  HAL_NVIC_SetPriority(EXTI9_5_IRQn, 5, 0);
  HAL_NVIC_EnableIRQ(EXTI9_5_IRQn);

  HAL_NVIC_SetPriority(EXTI15_10_IRQn, 5, 0);
  HAL_NVIC_EnableIRQ(EXTI15_10_IRQn);

}

void StartDefaultTask(void const * argument)
{
  /* init code for USB_DEVICE */
  MX_USB_DEVICE_Init();
  /* USER CODE BEGIN 5 */
  setup();

  /* Infinite loop */
  for(;;)
  {
    loop();
  }
  /* USER CODE END 5 */
}

void Error_Handler(void)
{
  /* USER CODE BEGIN Error_Handler_Debug */
#ifdef DEBUG
  __asm__("BKPT");
#else
  NVIC_SystemReset();
#endif
  /* USER CODE END Error_Handler_Debug */
}

#ifdef  USE_FULL_ASSERT
/**
  * @brief  Reports the name of the source file and the source line number
  *         where the assert_param error has occurred.
  * @param  file: pointer to the source file name
  * @param  line: assert_param error line source number
  * @retval None
  */
void assert_failed(uint8_t *file, uint32_t line)
{
  /* USER CODE BEGIN 6 */
#ifdef DEBUG
  __asm__("BKPT");
#else
  NVIC_SystemReset();
#endif
  /* USER CODE END 6 */
}
#endif /* USE_FULL_ASSERT */
